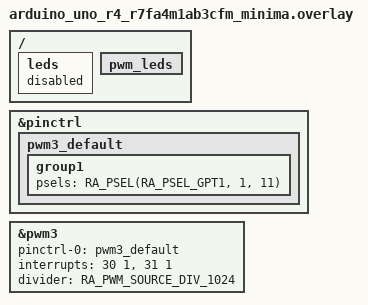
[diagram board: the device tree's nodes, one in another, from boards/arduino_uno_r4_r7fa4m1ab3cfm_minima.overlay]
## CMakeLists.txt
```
# SPDX-License-Identifier: Apache-2.0

cmake_minimum_required(VERSION 3.28.0)

find_package(Zephyr REQUIRED HINTS $ENV{ZEPHYR_BASE})
project(led_pwm)

FILE(GLOB app_sources src/*.c)
target_sources(app PRIVATE ${app_sources})
```

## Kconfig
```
# Copyright (c) 2024 TOKITA Hiroshi
# SPDX-License-Identifier: Apache-2.0

config BLINK_DELAY_SHORT
	int "Blinking delay for short cycle demo"
	default 100
	help
	  Specifies the LED on/off delay in milliseconds for short cycle
	  blinking demonstration.
	  If set to 0, the short-cycle blinking demo will not be performed.

config BLINK_DELAY_LONG
	int "Blinking delay for long cycle demo"
	default 1000
	help
	  Specifies the LED on/off delay in milliseconds for long cycle
	  blinking demonstration.
	  If set to 0, the long-cycle blinking demo will not be performed.

config FADE_DELAY
	int "Delay time for fade demo"
	default 10
	help
	  Specifies the delay in milliseconds for the fade demo of the
	  PWM-LED sample.
	  The brightness gradually increases by one level each time this
	  delay elapses.

config BLINK_DELAY_AUTO_FALLBACK
	bool "Enable automatic fallback to calculated delays"
	default y
	help
	  When enabled, if the configured blink delays fail (e.g., exceed
	  PWM period), the sample will automatically calculate appropriate
	  delays from the LED's PWM period.

config BLINK_DELAY_SHORT_LED_PERIOD_DIV
	int "Divisor for auto-calculating short blink delay from PWM period"
	default 10
	depends on BLINK_DELAY_AUTO_FALLBACK
	help
	  When CONFIG_BLINK_DELAY_SHORT exceeds the timer's range, this divisor
	  is used to automatically calculate the short blink delay from the
	  LED's PWM period defined in the devicetree.

	  Formula: delay_ms = (pwm_period_ms / DIVISOR / 2)

	  The division by 2 is because the delay applies to each phase
	  (on OR off) separately, not the total period.

config BLINK_DELAY_LONG_LED_PERIOD_DIV
	int "Divisor for auto-calculating long blink delay from PWM period"
	default 1
	depends on BLINK_DELAY_AUTO_FALLBACK
	help
	  When CONFIG_BLINK_DELAY_LONG exceeds the timer's range, this divisor
	  is used to automatically calculate the long blink delay from the
	  LED's PWM period defined in the devicetree.

	  Formula: delay_ms = (pwm_period_ms / DIVISOR / 2)

	  The division by 2 is because the delay applies to each phase
	  (on OR off) separately, not the total period.

source "Kconfig.zephyr"
```

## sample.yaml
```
sample:
  description: Demonstration of the PWM LED driver
  name: PWM LED sample
tests:
  sample.drivers.led.led_pwm:
    filter: dt_compat_enabled("pwm-leds")
    tags: LED
    depends_on: pwm
    platform_exclude: reel_board
    integration_platforms:
      - frdm_k22f
    timeout: 20
    harness: console
    harness_config:
      type: multi_line
      ordered: true
      regex:
        - "Testing LED \\d+"
        - "Turned on"
        - "Turned off"
        - "Increasing brightness gradually"
        - "Decreasing brightness gradually"
        - "Blinking on: ([0-9]+) msec, off: ([0-9]+) msec"
        - "(Blinking on: ([0-9]+) msec, off: ([0-9]+) msec|Cycle period not supported)"
        - "Turned off, loop end"
```

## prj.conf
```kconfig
CONFIG_LOG=y

CONFIG_LED=y

CONFIG_LOG_MODE_IMMEDIATE=y
```

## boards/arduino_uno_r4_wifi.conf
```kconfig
CONFIG_BLINK_DELAY_SHORT=20
CONFIG_BLINK_DELAY_LONG=65
CONFIG_FADE_DELAY=15
```

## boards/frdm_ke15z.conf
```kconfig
# FTM on KE15Z tops out at ~1048 ms period (SOSC 8 MHz / prescaler 128).
# led_blink(on, off) = total period, so cap each delay at ~500 ms.
CONFIG_BLINK_DELAY_LONG=500
```

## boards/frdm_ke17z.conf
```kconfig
# FTM on KE17Z tops out at ~1048 ms period (SOSC 8 MHz / prescaler 128).
# led_blink(on, off) = total period, so cap each delay at ~500 ms.
CONFIG_BLINK_DELAY_LONG=500
```

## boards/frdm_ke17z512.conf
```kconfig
# FTM on KE17Z512 tops out at ~1048 ms period (SOSC 8 MHz / prescaler 128).
# led_blink(on, off) = total period, so cap each delay at ~500 ms.
CONFIG_BLINK_DELAY_LONG=500
```

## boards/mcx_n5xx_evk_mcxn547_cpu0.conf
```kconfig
CONFIG_BLINK_DELAY_SHORT=2
CONFIG_BLINK_DELAY_LONG=20
```

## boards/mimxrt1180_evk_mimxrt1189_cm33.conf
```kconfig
CONFIG_BLINK_DELAY_SHORT=10
CONFIG_BLINK_DELAY_LONG=30
```

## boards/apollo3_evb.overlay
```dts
/*
 * SPDX-License-Identifier: Apache-2.0
 *
 * Copyright (c) 2025 Ambiq
 */

/ {
	/* do not define the led on the pa5 but a pwmleds */
	leds {
		status = "disabled";
	};
};

&pwmleds {
	/* NOTE: enable here because it is disabled by default */
	status = "okay";
};

&pwm2 {
	status = "okay";
};
```

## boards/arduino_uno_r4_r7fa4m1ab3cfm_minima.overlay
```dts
#include <zephyr/dt-bindings/pwm/pwm.h>
#include <zephyr/dt-bindings/pwm/ra_pwm.h>

/ {
	leds {
		status = "disabled";
	};

	pwm_leds {
		status = "okay";
	};
};

&pinctrl {
	pwm3_default: pwm3_default {
		group1 {
			/* GTIOC3A */
			psels = <RA_PSEL(RA_PSEL_GPT1, 1, 11)>;
		};
	};
};

&pwm3 {
	pinctrl-0 = <&pwm3_default>;
	pinctrl-names = "default";
	interrupts = <30 1>, <31 1>;
	interrupt-names = "gtioca", "overflow";
	divider = <RA_PWM_SOURCE_DIV_1024>;
	status = "okay";
};
```

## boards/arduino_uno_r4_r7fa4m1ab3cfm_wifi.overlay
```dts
#include <zephyr/dt-bindings/pwm/pwm.h>
#include <zephyr/dt-bindings/pwm/ra_pwm.h>

/ {
	leds {
		status = "disabled";
	};

	pwm_leds {
		status = "okay";
	};
};

&pinctrl {
	pwm2_default: pwm2_default {
		group1 {
			/* GTIOC2B */
			psels = <RA_PSEL(RA_PSEL_GPT1, 1, 2)>;
		};
	};
};

&pwm2 {
	pinctrl-0 = <&pwm2_default>;
	pinctrl-names = "default";
	interrupts = <30 1>, <31 1>;
	interrupt-names = "gtioca", "overflow";
	divider = <RA_PWM_SOURCE_DIV_1024>;
	status = "okay";
};
```

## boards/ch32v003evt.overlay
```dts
/*
 * Copyright (c) 2025 Michael Hope <michaelh@juju.nz>
 *
 * SPDX-License-Identifier: Apache-2.0
 */

/ {
	leds {
		status = "disabled";
	};
};

&pwmleds {
	status = "okay";
};

&tim2 {
	/*
	 * The sample blinks the LED at 0.5 Hz, ceil(48 MHz / 65536 / 0.5 Hz)
	 * is 1465, and the prescaler property is one less than that.
	 */
	prescaler = <1464>;
	status = "okay";
};

&pwm2 {
	pinctrl-0 = <&red_pwm_pinctrl>;
	pinctrl-names = "default";
	status = "okay";
};
```

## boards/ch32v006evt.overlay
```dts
/*
 * Copyright (c) 2025 Michael Hope <michaelh@juju.nz>
 *
 * SPDX-License-Identifier: Apache-2.0
 */

/ {
	leds {
		status = "disabled";
	};

	pwmleds {
		status = "okay";
	};
};

&tim2 {
	/*
	 * The sample blinks the LED at 0.5 Hz, ceil(48 MHz / 65536 / 0.5 Hz)
	 * is 1465, and the prescaler property is one less than that.
	 */
	prescaler = <1464>;
	status = "okay";
};

&pwm2 {
	pinctrl-0 = <&blue_pwm_pinctrl>;
	pinctrl-names = "default";
	status = "okay";
};
```

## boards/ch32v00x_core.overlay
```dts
/*
 * SPDX-FileCopyrightText: Copyright Michael Hope <michaelh@juju.nz>
 *
 * SPDX-License-Identifier: Apache-2.0
 */

/ {
	leds {
		status = "disabled";
	};

	pwmleds {
		status = "okay";
	};
};

&tim1 {
	/*
	 * The sample blinks the LED at 0.5 Hz, ceil(48 MHz / 65536 / 0.5 Hz)
	 * is 1465, and the prescaler property is one less than that.
	 */
	prescaler = <1464>;
	status = "okay";
};

&pwm1 {
	pinctrl-0 = <&blue_pwm_pinctrl>;
	pinctrl-names = "default";
	status = "okay";
};
```

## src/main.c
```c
/*
 * Copyright (c) 2020 Seagate Technology LLC
 *
 * SPDX-License-Identifier: Apache-2.0
 */

#include <zephyr/device.h>
#include <zephyr/devicetree.h>
#include <errno.h>
#include <zephyr/drivers/led.h>
#include <zephyr/sys/util.h>
#include <zephyr/kernel.h>

#include <zephyr/logging/log.h>
LOG_MODULE_REGISTER(main, CONFIG_LOG_DEFAULT_LEVEL);

#define LED_PWM_NODE_ID	 DT_COMPAT_GET_ANY_STATUS_OKAY(pwm_leds)

const char *led_label[] = {
	DT_FOREACH_CHILD_SEP_VARGS(LED_PWM_NODE_ID, DT_PROP_OR, (,), label, NULL)
};

#if CONFIG_BLINK_DELAY_AUTO_FALLBACK
/* Generic macro to get PWM period for each child */
#define GET_LED_PERIOD(node_id) DT_PWMS_PERIOD(node_id),

/* Create array of PWM periods */
static const uint32_t led_periods_ns[] = {
	DT_FOREACH_CHILD(LED_PWM_NODE_ID, GET_LED_PERIOD)
};

/**
 * @brief Automatically calculate and apply a fallback blink delay for an LED
 *
 * This function calculates an appropriate blink delay based on the LED's PWM period
 * when the requested delay exceeds the PWM hardware capabilities. The delay is
 * calculated by dividing the PWM period by a divisor and ensuring a minimum
 * visibility threshold.
 *
 * @param led_pwm LED PWM device
 * @param led LED index to configure
 * @param led_delay Pointer to store the calculated delay (in milliseconds)
 * @param div Divisor to scale down the PWM period for delay calculation
 *
 * @return 0 on success, negative error code on failure from led_blink()
 */
static int blink_delay_auto_fallback(const struct device *led_pwm, uint8_t led,
					uint32_t *led_delay, uint32_t div)
{
	*led_delay = led_periods_ns[led] / 1000000 / div / 2;
	/* Ensure minimum 1ms for visibility */
	*led_delay = MAX(1, *led_delay);

	LOG_INF("Auto-calculated delay: %u ms.", *led_delay);

	return led_blink(led_pwm, led, *led_delay, *led_delay);
}
#endif

const int num_leds = ARRAY_SIZE(led_label);

#define MAX_BRIGHTNESS	100

/**
 * @brief Run tests on a single LED using the LED API syscalls.
 *
 * @param led_pwm LED PWM device.
 * @param led Number of the LED to test.
 */
static void run_led_test(const struct device *led_pwm, uint8_t led)
{
	int err;
	int16_t level;
	uint32_t led_delay;

	LOG_INF("Testing LED %d - %s", led, led_label[led] ? : "no label");

	/* Turn LED on. */
	err = led_on(led_pwm, led);
	if (err < 0) {
		LOG_ERROR("err=%d", err);
		return;
	}
	LOG_INF("  Turned on");
	k_sleep(K_MSEC(1000));

	/* Turn LED off. */
	err = led_off(led_pwm, led);
	if (err < 0) {
		LOG_ERROR("err=%d", err);
		return;
	}
	LOG_INF("  Turned off");
	k_sleep(K_MSEC(1000));

	/* Increase LED brightness gradually up to the maximum level. */
	LOG_INF("  Increasing brightness gradually");
	for (level = 0; level <= MAX_BRIGHTNESS; level++) {
		err = led_set_brightness(led_pwm, led, level);
		if (err < 0) {
			LOG_ERROR("err=%d brightness=%d\n", err, level);
			return;
		}
		k_sleep(K_MSEC(CONFIG_FADE_DELAY));
	}
	k_sleep(K_MSEC(1000));

	/* Decrease LED brightness gradually down to the minimum level. */
	LOG_INF("  Decreasing brightness gradually");
	for (level = MAX_BRIGHTNESS; level >= 0; level--) {
		err = led_set_brightness(led_pwm, led, level);
		if (err < 0) {
			LOG_ERROR("err=%d brightness=%d\n", err, level);
			return;
		}
		k_sleep(K_MSEC(CONFIG_FADE_DELAY));
	}
	k_sleep(K_MSEC(1000));

#if CONFIG_BLINK_DELAY_SHORT > 0
	led_delay = (uint32_t)CONFIG_BLINK_DELAY_SHORT;
	/* Start LED blinking (short cycle) */
	err = led_blink(led_pwm, led, led_delay, led_delay);
	if (err < 0) {
#if CONFIG_BLINK_DELAY_AUTO_FALLBACK && CONFIG_BLINK_DELAY_SHORT_LED_PERIOD_DIV > 0
		LOG_INF("CONFIG_BLINK_DELAY_SHORT (%u ms) exceeds PWM capabilities for LED %u.",
			led_delay, led);
		err = blink_delay_auto_fallback(led_pwm, led, &led_delay,
			(uint32_t)CONFIG_BLINK_DELAY_SHORT_LED_PERIOD_DIV);
#endif
		if (err < 0) {
			LOG_ERROR("err=%d", err);
			return;
		}
	}
	LOG_INF("  Blinking on: %u msec, off: %u msec", led_delay, led_delay);
	k_sleep(K_MSEC(5000));
#endif

#if CONFIG_BLINK_DELAY_LONG > 0
	led_delay = (uint32_t)CONFIG_BLINK_DELAY_LONG;
	/* Start LED blinking (long cycle) */
	err = led_blink(led_pwm, led, led_delay, led_delay);
	if (err < 0) {
#if CONFIG_BLINK_DELAY_AUTO_FALLBACK && CONFIG_BLINK_DELAY_LONG_LED_PERIOD_DIV > 0
		LOG_INF("CONFIG_BLINK_DELAY_LONG (%u ms) exceeds PWM capabilities for LED %u.",
			led_delay, led);
		err = blink_delay_auto_fallback(led_pwm, led, &led_delay,
			(uint32_t)CONFIG_BLINK_DELAY_LONG_LED_PERIOD_DIV);
#endif
		if (err < 0) {
			LOG_ERROR("err=%d", err);
			LOG_INF("  Cycle period not supported - on: %u msec, "
				"off: %u msec", led_delay, led_delay);
		}
	}
	LOG_INF("  Blinking on: %u msec, off: %u msec", led_delay, led_delay);
	k_sleep(K_MSEC(5000));
#endif

	/* Turn LED off. */
	err = led_off(led_pwm, led);
	if (err < 0) {
		LOG_ERROR("err=%d", err);
		return;
	}
	LOG_INF("  Turned off, loop end");
}

int main(void)
{
	const struct device *led_pwm;
	uint8_t led;

	led_pwm = DEVICE_DT_GET(LED_PWM_NODE_ID);
	if (!device_is_ready(led_pwm)) {
		LOG_ERROR("Device %s is not ready", led_pwm->name);
		return 0;
	}

	if (!num_leds) {
		LOG_ERROR("No LEDs found for %s", led_pwm->name);
		return 0;
	}

	do {
		for (led = 0; led < num_leds; led++) {
			run_led_test(led_pwm, led);
		}
	} while (true);
	return 0;
}
```
